# MKM34Z7 register map
Vendor: Freescale Semiconductor, Inc.; Series: Kinetis_M; File version: 1.6
CPU: CM0PLUS r0p0, little endian, no MPU, no FPU, VTOR, 2 interrupt priority bits
Registers are 32-bit, read-write, reset 0x0 unless marked. A register's access mark holds for its fields unless they carry their own. Offsets are from the block's base; [hi:lo] are bit positions; {n}, {i} and the like mark numbered series; 'fields as' and 'values as' point back to an identical list.

## RCM — Reset Control Module
Base 0x4007B000; register names take the prefix RCM_
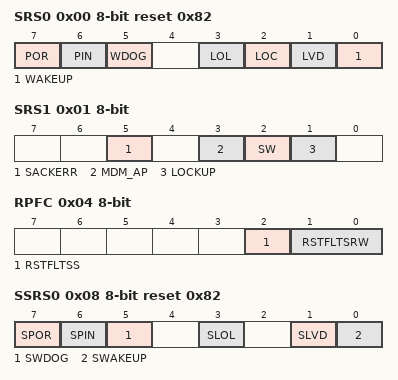
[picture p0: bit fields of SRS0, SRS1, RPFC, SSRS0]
0x00 SRS0 8-bit ro reset 0x82 — System Reset Status Register 0
  [7] POR — Power-On Reset
    0=Reset not caused by POR; 1=Reset caused by POR
  [6] PIN — External Reset Pin
    0=Reset not caused by external reset pin; 1=Reset caused by external reset pin
  [5] WDOG — Watchdog
    0=Reset not caused by watchdog timeout; 1=Reset caused by watchdog timeout
  [3] LOL — Loss-of-Lock Reset
    0=Reset not caused by a loss of lock in the PLL; 1=Reset caused by a loss of lock in the PLL
  [2] LOC — Loss-of-Clock Reset
    0=Reset not caused by a loss of external clock; 1=Reset caused by a loss of external clock
  [1] LVD — Low-Voltage Detect Reset
    0=Reset not caused by LVD trip or POR; 1=Reset caused by LVD trip or POR
  [0] WAKEUP — Low Leakage Wakeup Reset
    0=Reset not caused by wakeup source; 1=Reset caused by wakeup source
0x01 SRS1 8-bit ro — System Reset Status Register 1
  [5] SACKERR — Stop Mode Acknowledge Error Reset
    0=Reset not caused by peripheral failure to acknowledge attempt to enter stop mode; 1=Reset caused by peripheral failure to acknowledge attempt to enter stop mode
  [3] MDM_AP — MDM-AP System Reset Request
    0=Reset not caused by host debugger system setting of the System Reset Request bit; 1=Reset caused by host debugger system setting of the System Reset Request bit
  [2] SW — Software
    0=Reset not caused by software setting of SYSRESETREQ bit; 1=Reset caused by software setting of SYSRESETREQ bit
  [1] LOCKUP — Core Lockup
    0=Reset not caused by core LOCKUP event; 1=Reset caused by core LOCKUP event
0x04 RPFC 8-bit — Reset Pin Filter Control register
  [2] RSTFLTSS — Reset Pin Filter Select in Stop Mode
    0=All filtering disabled; 1=LPO clock filter enabled
  [1:0] RSTFLTSRW — Reset Pin Filter Select in Run and Wait Modes
    0=All filtering disabled; 1=Bus clock filter enabled for normal operation; 2=LPO clock filter enabled for normal operation
0x05 RPFW 8-bit — Reset Pin Filter Width register
  [4:0] RSTFLTSEL — Reset Pin Filter Bus Clock Select
    {v}=Bus clock filter count is {v+1} (v=0..31)
0x08 SSRS0 8-bit reset 0x82 — Sticky System Reset Status Register 0
  [7] SPOR — Sticky Power-On Reset
    0=Reset not caused by POR; 1=Reset caused by POR
  [6] SPIN — Sticky External Reset Pin
    values as SRS0.PIN
  [5] SWDOG — Sticky Watchdog
    values as SRS0.WDOG
  [3] SLOL — Sticky Loss-of-Lock Reset
    values as SRS0.LOL
  [1] SLVD — Sticky Low-Voltage Detect Reset
    values as SRS0.LVD
  [0] SWAKEUP — Sticky Low Leakage Wakeup Reset
    values as SRS0.WAKEUP
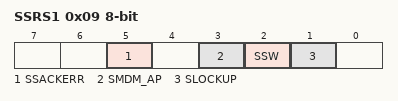
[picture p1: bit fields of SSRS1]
0x09 SSRS1 8-bit — Sticky System Reset Status Register 1
  [5] SSACKERR — Sticky Stop Mode Acknowledge Error Reset
    values as SRS1.SACKERR
  [3] SMDM_AP — Sticky MDM-AP System Reset Request
    values as SRS1.MDM_AP
  [2] SSW — Sticky Software
    values as SRS1.SW
  [1] SLOCKUP — Sticky Core Lockup
    values as SRS1.LOCKUP

## LLWU — Low leakage wakeup unit
Base 0x4007C000; register names take the prefix LLWU_
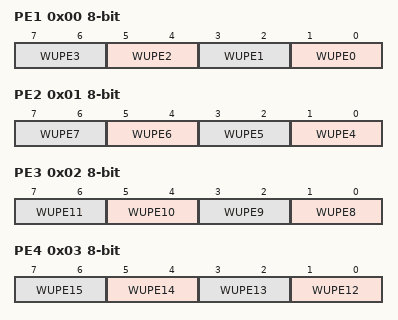
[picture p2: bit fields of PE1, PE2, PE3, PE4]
0x00 PE1 8-bit — LLWU Pin Enable 1 register
  [all] fields
    0=External input pin disabled as wakeup input; 1=External input pin enabled with rising edge detection; 2=External input pin enabled with falling edge detection; 3=External input pin enabled with any change detection
  [2n+1:2n] WUPE{n} (n=0..3) — Wakeup Pin Enable For LLWU_P{n}
0x01 PE2 8-bit — LLWU Pin Enable 2 register
  [all] fields
    values as the fields of PE1
  [2n-7:2n-8] WUPE{n} (n=4..7) — Wakeup Pin Enable For LLWU_P{n}
0x02 PE3 8-bit — LLWU Pin Enable 3 register
  [all] fields
    values as the fields of PE1
  [2n-15:2n-16] WUPE{n} (n=8..11) — Wakeup Pin Enable For LLWU_P{n}
0x03 PE4 8-bit — LLWU Pin Enable 4 register
  [all] fields
    values as the fields of PE1
  [2n-23:2n-24] WUPE{n} (n=12..15) — Wakeup Pin Enable For LLWU_P{n}
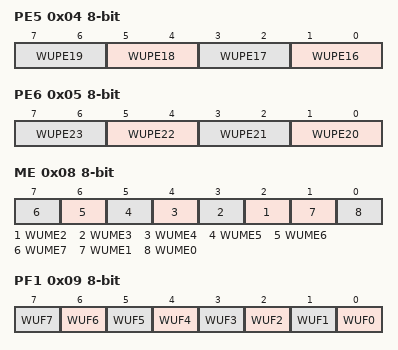
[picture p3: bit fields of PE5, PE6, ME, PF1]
0x04 PE5 8-bit — LLWU Pin Enable 5 register
  [all] fields
    values as the fields of PE1
  [2n-31:2n-32] WUPE{n} (n=16..19) — Wakeup Pin Enable For LLWU_P{n}
0x05 PE6 8-bit — LLWU Pin Enable 6 register
  [all] fields
    values as the fields of PE1
  [2n-39:2n-40] WUPE{n} (n=20..23) — Wakeup Pin Enable For LLWU_P{n}
0x08 ME 8-bit — LLWU Module Enable register
  [all] fields
    0=Internal module flag not used as wakeup source; 1=Internal module flag used as wakeup source
  [n] WUME{n} (n=2..7) — Wakeup Module Enable For Module {n}
  [1] WUME1 — Wakeup Module Enable for Module 1
  [0] WUME0 — Wakeup Module Enable For Module 0
0x09 PF1 8-bit — LLWU Pin Flag 1 register
  [n] WUF{n} (n=0..7) — Wakeup Flag For LLWU_P{n}
    0=LLWU_P{n} input was not a wakeup source; 1=LLWU_P{n} input was a wakeup source
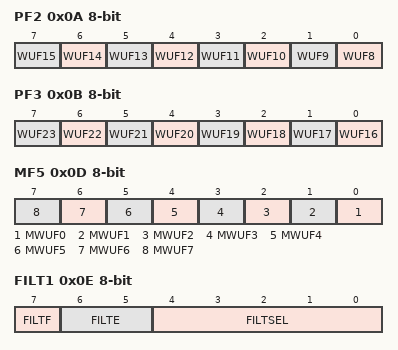
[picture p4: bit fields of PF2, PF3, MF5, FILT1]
0x0A PF2 8-bit — LLWU Pin Flag 2 register
  [n-8] WUF{n} (n=8..15) — Wakeup Flag For LLWU_P{n}
    values as PF1.WUF0
0x0B PF3 8-bit — LLWU Pin Flag 3 register
  [n-16] WUF{n} (n=16..23) — Wakeup Flag For LLWU_P{n}
    values as PF1.WUF0
0x0D MF5 8-bit ro — LLWU Module Flag 5 register
  [n] MWUF{n} (n=0..7) — Wakeup flag For module {n}
    0=Module {n} input was not a wakeup source; 1=Module {n} input was a wakeup source
0x0E FILT1 8-bit — LLWU Pin Filter 1 register
  [7] FILTF — Filter Detect Flag
    0=Pin Filter 1 was not a wakeup source; 1=Pin Filter 1 was a wakeup source
  [6:5] FILTE — Digital Filter On External Pin
    0=Filter disabled; 1=Filter posedge detect enabled; 2=Filter negedge detect enabled; 3=Filter any edge detect enabled
  [4:0] FILTSEL — Filter Pin Select
    0=Select LLWU_P0 for filter; 31=Select LLWU_P31 for filter
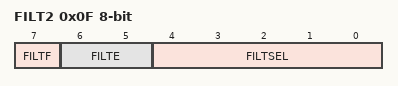
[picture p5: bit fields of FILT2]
0x0F FILT2 8-bit — LLWU Pin Filter 2 register
  [7] FILTF — Filter Detect Flag
    0=Pin Filter 2 was not a wakeup source; 1=Pin Filter 2 was a wakeup source
  [6:5] FILTE — Digital Filter On External Pin
    values as FILT1.FILTE
  [4:0] FILTSEL — Filter Pin Select
    0=Select LLWU_P0 for filter; 31=Select LLWU_P31 for filter
